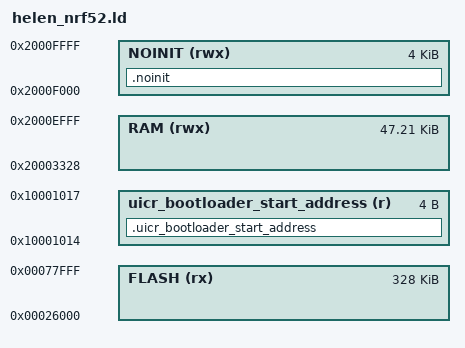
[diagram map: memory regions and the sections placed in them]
/* Linker script to configure memory regions. */

SEARCH_DIR(.)
GROUP(-lgcc -lc -lnosys)

MEMORY
{
  FLASH (rx)                        : ORIGIN = 0x26000,    LENGTH = 0x52000
  RAM (rwx)                         : ORIGIN = 0x20003328, LENGTH = 0xBCD8
  NOINIT (rwx)                      : ORIGIN = 0x2000F000, LENGTH = 0x1000
  uicr_bootloader_start_address (r) : ORIGIN = 0x10001014, LENGTH = 0x4
}

SECTIONS
{
  . = ALIGN(4);
  .uicr_bootloader_start_address :
  {
    PROVIDE(__start_uicr_bootloader_start_address = .);
    KEEP(*(SORT(.uicr_bootloader_start_address*)))
    PROVIDE(__stop_uicr_bootloader_start_address = .);
  } > uicr_bootloader_start_address

  .noinit(NOLOAD) :
  {
    KEEP(*(.noinit))
  } > NOINIT
}

SECTIONS
{
  . = ALIGN(4);
  .mem_section_dummy_ram :
  {
  }
  .log_dynamic_data :
  {
    PROVIDE(__start_log_dynamic_data = .);
    KEEP(*(SORT(.log_dynamic_data*)))
    PROVIDE(__stop_log_dynamic_data = .);
  } > RAM
  .log_filter_data :
  {
    PROVIDE(__start_log_filter_data = .);
    KEEP(*(SORT(.log_filter_data*)))
    PROVIDE(__stop_log_filter_data = .);
  } > RAM
  .fs_data :
  {
    PROVIDE(__start_fs_data = .);
    KEEP(*(.fs_data))
    PROVIDE(__stop_fs_data = .);
  } > RAM

} INSERT AFTER .data;

SECTIONS
{
  .mem_section_dummy_rom :
  {
  }
  .sdh_ble_observers :
  {
    PROVIDE(__start_sdh_ble_observers = .);
    KEEP(*(SORT(.sdh_ble_observers*)))
    PROVIDE(__stop_sdh_ble_observers = .);
  } > FLASH
  .sdh_soc_observers :
  {
    PROVIDE(__start_sdh_soc_observers = .);
    KEEP(*(SORT(.sdh_soc_observers*)))
    PROVIDE(__stop_sdh_soc_observers = .);
  } > FLASH
  .pwr_mgmt_data :
  {
    PROVIDE(__start_pwr_mgmt_data = .);
    KEEP(*(SORT(.pwr_mgmt_data*)))
    PROVIDE(__stop_pwr_mgmt_data = .);
  } > FLASH
  .log_const_data :
  {
    PROVIDE(__start_log_const_data = .);
    KEEP(*(SORT(.log_const_data*)))
    PROVIDE(__stop_log_const_data = .);
  } > FLASH
  .sdh_req_observers :
  {
    PROVIDE(__start_sdh_req_observers = .);
    KEEP(*(SORT(.sdh_req_observers*)))
    PROVIDE(__stop_sdh_req_observers = .);
  } > FLASH
  .sdh_state_observers :
  {
    PROVIDE(__start_sdh_state_observers = .);
    KEEP(*(SORT(.sdh_state_observers*)))
    PROVIDE(__stop_sdh_state_observers = .);
  } > FLASH
  .sdh_stack_observers :
  {
    PROVIDE(__start_sdh_stack_observers = .);
    KEEP(*(SORT(.sdh_stack_observers*)))
    PROVIDE(__stop_sdh_stack_observers = .);
  } > FLASH
  .log_backends :
  {
    PROVIDE(__start_log_backends = .);
    KEEP(*(SORT(.log_backends*)))
    PROVIDE(__stop_log_backends = .);
  } > FLASH
  .nrf_balloc :
  {
    PROVIDE(__start_nrf_balloc = .);
    KEEP(*(.nrf_balloc))
    PROVIDE(__stop_nrf_balloc = .);
  } > FLASH
  .remote_driver :
  {
    PROVIDE(__start_remote_driver = .);
    KEEP(*(.remote_driver))
    PROVIDE(__stop_remote_driver = .);
  } > FLASH
  .debug_commands :
  {
    PROVIDE(__start_debug_commands = .);
    KEEP(*(.debug_commands))
    PROVIDE(__stop_debug_commands = .);
  } > FLASH
  .btle_service :
  {
    PROVIDE(__start_btle_service = .);
    KEEP(*(.btle_service))
    PROVIDE(__stop_btle_service = .);
  } > FLASH
  .cell_data :
  {
    PROVIDE(__start_cell_data = .);
    KEEP(*(.cell_data))
    PROVIDE(__stop_cell_data = .);
  } > FLASH

} INSERT AFTER .text


INCLUDE "nrf_common.ld"
